# psc register map
Vendor: Texas Instruments
Peripheral module from a debugger description file (folder Keystone2).
Registers are 32-bit, read-write, no defined reset value unless marked. A register's access mark holds for its fields unless they carry their own. Offsets are as the file gives them; lines under a group give offsets from that group; [hi:lo] are bit positions; {n}, {i} and the like mark numbered series; 'fields as' and 'values as' point back to an identical list; <NAME> marks a mode.

## PSC
0x00 pid
0x14 vcntlid
  [21:16] vcntl
0x120 ptcmd
  [31:0] go
0x128 ptstat
  [31:0] gostat
0x200 pdstat — (1 of 32, stride 4)
  [1:0] state
0x300 pdctl — (1 of 32, stride 4)
  [0] next
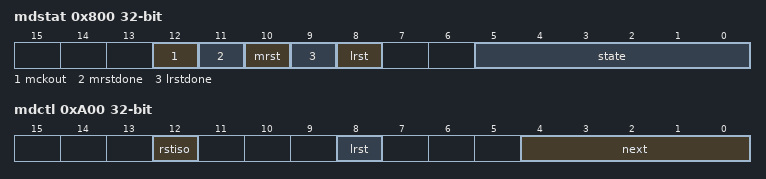
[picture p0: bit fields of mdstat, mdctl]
0x800 mdstat — (1 of 64, stride 4)
  [12] mckout, [11] mrstdone, [10] mrst, [9] lrstdone, [8] lrst, [5:0] state
0xA00 mdctl — (1 of 64, stride 4)
  [12] rstiso, [8] lrst, [4:0] next
